AUTOSAR XML (schema 4-2-2)
package /ComponentTypes
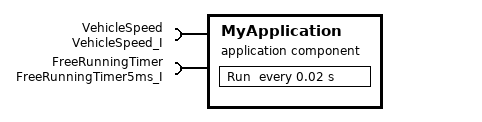
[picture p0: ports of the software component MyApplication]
  application sw component type MyApplication
    require port VehicleSpeed: nonqueued-receiver-com-spec{data-element=VehicleSpeed, filter=data-filter-type=ALWAYS, init-value=constant-reference=VehicleSpeed_IV}, required-interface=VehicleSpeed_I
    require port FreeRunningTimer: required-com-specs=[GetTime, IsTimerElapsed], required-interface=FreeRunningTimer5ms_I
    behavior MyApplication_InternalBehavior
      timing event TMT_Run: start-on-event=Run, period=0.02
      port-api-options:
        enable-take-address=false, indirect-api=false, port=FreeRunningTimer
        enable-take-address=false, indirect-api=false, port=VehicleSpeed
      runnable Run
        data-receive-point-by-arguments:
          access REC_VehicleSpeed_VehicleSpeed: accessed-variable=VehicleSpeed.VehicleSpeed
        sync call SC_FreeRunningTimer_GetTime: operation=FreeRunningTimer.GetTime, timeout=0
        sync call SC_FreeRunningTimer_IsTimerElapsed: operation=FreeRunningTimer.IsTimerElapsed, timeout=0
  swc implementation MyApplication_Implementation: behavior=MyApplication_InternalBehavior
    code-descriptors:
      code Default: artifact-descriptors=autosar-engineering-object={short-label=Default, category=SWSRC}
